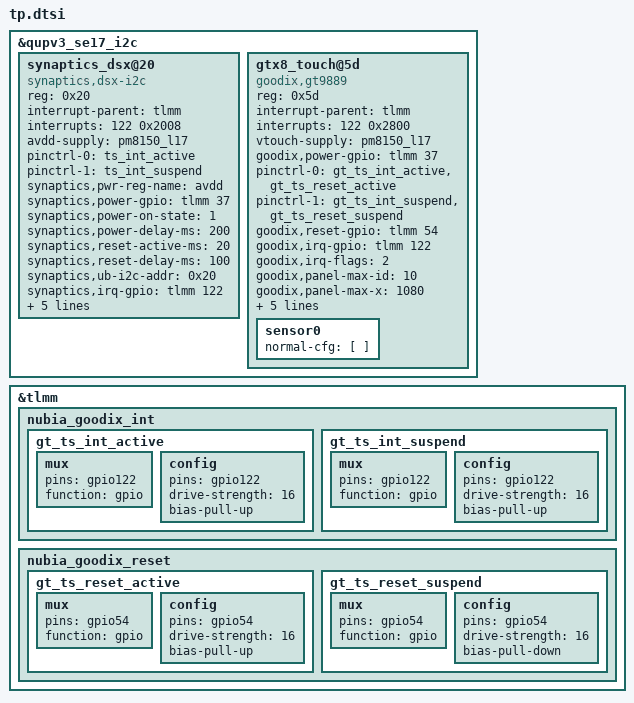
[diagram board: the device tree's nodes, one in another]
/*
 * Copyright (c) 2015-2016, The Linux Foundation. All rights reserved.
 *
 * This program is free software; you can redistribute it and/or modify
 * it under the terms of the GNU General Public License version 2 and
 * only version 2 as published by the Free Software Foundation.
 *
 * This program is distributed in the hope that it will be useful,
 * but WITHOUT ANY WARRANTY; without even the implied warranty of
 * MERCHANTABILITY or FITNESS FOR A PARTICULAR PURPOSE.  See the
 * GNU General Public License for more details.
 */

&qupv3_se17_i2c {
		status = "okay";
                synaptics_dsx@20 {
                        compatible = "synaptics,dsx-i2c";
                        reg = <0x20>;
                        interrupt-parent = <&tlmm>;
                        interrupts = <122 0x2008>;
                        //vdd-supply = <&pm8150_l14>;
                        avdd-supply = <&pm8150_l17>;
                        pinctrl-names = "pmx_ts_active", "pmx_ts_suspend";
                        pinctrl-0 = <&ts_int_active>;
                        pinctrl-1 = <&ts_int_suspend>;
                        synaptics,pwr-reg-name = "avdd";
                        //synaptics,bus-reg-name = "vdd";
                        synaptics,power-gpio = <&tlmm 37 0x00>;
                        synaptics,power-on-state = <1>;
                        synaptics,power-delay-ms = <200>;
                        synaptics,reset-active-ms = <20>;
                        synaptics,reset-delay-ms = <100>;
                        synaptics,ub-i2c-addr = <0x20>;
                        synaptics,irq-gpio = <&tlmm 122 0x2008>;
                        synaptics,reset-gpio = <&tlmm 54 0x0>;
                        synaptics,firmware-image-name = "nubia_tp_jdi_fw.img";
                        synaptics,irq-on-state = <0>;
                        synaptics,reset-on-state = <0>;
                };
		gtx8_touch@5d {
			compatible = "goodix,gt9889";
			reg = <0x5d>;
			status = "ok";
			interrupt-parent = <&tlmm>;
			interrupts = <122 0x2800>;
			vtouch-supply = <&pm8150_l17>;
			goodix,power-gpio = <&tlmm 37 0x00>;
			pinctrl-names = "pmx_ts_active","pmx_ts_suspend";
			pinctrl-0 = <&gt_ts_int_active &gt_ts_reset_active>;
			pinctrl-1 = <&gt_ts_int_suspend &gt_ts_reset_suspend>;
			goodix,reset-gpio = <&tlmm 54 0x0>;
			goodix,irq-gpio = <&tlmm 122 0x2800>;
			goodix,irq-flags = <2>; /* 1:trigger rising, 2:trigger falling;*/
			goodix,panel-max-id = <10>;
			goodix,panel-max-x = <1080>;
			goodix,panel-max-y = <2340>;
			goodix,panel-max-w = <512>;
			goodix,panel-max-p = <512>;
			goodix,power-on-delay-us = <30000>; /*30ms*/
			goodix,power-off-delay-us = <5000>;
			/*goodix,pen-enable;
			goodix,key-of-pen = <331 332>;*/ /*BTN_STYLUS, BTN_STYLUS2*/
			sensor0 {
				normal-cfg = [
				];
			};
		};
};


&tlmm {
        nubia_goodix_int {
                gt_ts_int_active: gt_ts_int_active {
                        mux {
                                pins = "gpio122";
                                function = "gpio";
                        };
                        config {
                                pins = "gpio122";
                                drive-strength = <16>;
                                bias-pull-up;
                        };
                };
                gt_ts_int_suspend: gt_ts_int_suspend {
                        mux {
                                pins = "gpio122";
                                function = "gpio";
                        };
                        config {
                                pins = "gpio122";
                                drive-strength = <16>;
                                bias-pull-up;
                        };
                };
        };

        nubia_goodix_reset {
                gt_ts_reset_active: gt_ts_reset_active {
                        mux {
                                pins = "gpio54";
                                function = "gpio";
                        };
                        config {
                                pins = "gpio54";
                                drive-strength = <16>;
                                bias-pull-up;
                        };
                };
                gt_ts_reset_suspend: gt_ts_reset_suspend {
                        mux {
                                pins = "gpio54";
                                function = "gpio";
                        };
                        config {
                                pins = "gpio54";
                                drive-strength = <16>;
                                bias-pull-down;
                        };
                };
        };
};

